# M460_v1 register map
File version: 1.0
Registers are 32-bit, read-write, reset 0x0 unless marked. A register's access mark holds for its fields unless they carry their own. Offsets are from the block's base; [hi:lo] are bit positions; lines under a group give offsets from that group.

## EMAC0 (part 1 of 2) — EMAC Register Map
Base 0x40012000
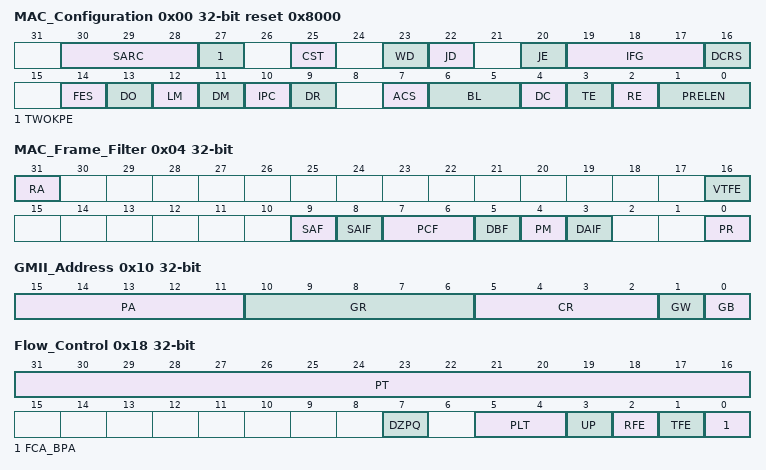
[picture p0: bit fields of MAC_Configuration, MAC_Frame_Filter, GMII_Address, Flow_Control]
0x00 MAC_Configuration reset 0x8000 — Register 0 (MAC Configuration Register)
  [30:28] SARC — Source Address Insertion or Replacement Control. This field controls the source address insertion or replacement for all transmitted frames. Bit 30 specifies which MAC Address register (0 or 1) is used for source address insertion or replacement based on the values of Bits [29:28]: If Bit 30 is set to 0, the MAC replaces the content of the MAC Address 0 registers (registers 16 and 17) in the SA field of all transmitted frames. If Bit 30 is set to 1, the MAC replaces the content of the MAC Address 1 registers (registers 18 and 19) in the SA field of all transmitted frames. Note: Changes to this field take effect only on the start of a frame. If you write this register field when a frame is being transmitted, only the subsequent frame can use the updated value, that is, the current frame does not use the updated value.
  [27] TWOKPE — IEEE 802.3as Support for 2K Packets. When set, the MAC considers all frames, with up to 2,000 bytes length, as normal packets. When Bit 20 (JE) is not set, the MAC considers all received frames of size more than 2 Kbytes as Giant frames. When this bit is reset and Bit 20 (JE) is not set, the MAC considers all received frames of size more than 1,518 bytes (1,522 bytes for tagged) as Giant frames. When Bit 20 is set, setting this bit has no effect on Giant Frame status.
  [25] CST — CRC Stripping for Type Frames. When this bit is set, the last 4 bytes (FCS) of all frames of Ether type (Length/Type field greater than or equal to 1,536) are stripped and dropped before forwarding the frame to the application. This function is not valid when the IP Checksum Engine (Type 1) is enabled in the MAC receiver. This function is valid when Type 2 Checksum Offload Engine is enabled.
  [23] WD — Watchdog Disable. When this bit is set, the MAC disables the watchdog timer on the receiver. The MAC can receive frames of up to 16,384 bytes. When this bit is reset, the MAC does not allow a receive frame which more than 2,048 bytes (10,240 if JE is set high) or the value programmed in Register 55 (Watchdog Timeout Register). The MAC cuts off any bytes received after the watchdog limit number of bytes.
  [22] JD — Jabber Disable. When this bit is set, the MAC disables the jabber timer on the transmitter. The MAC can transfer frames of up to 16,384 bytes. When this bit is reset, the MAC cuts off the transmitter if the application sends out more than 2,048 bytes of data (10,240 if JE is set high) during transmission.
  [20] JE — Jumbo Frame Enable. When this bit is set, the MAC allows Jumbo frames of 9,018 bytes (9,022 bytes for VLAN tagged frames) without reporting a giant frame error in the receive frame status.
  [19:17] IFG — Inter-Frame Gap. These bits control the minimum IFG between frames during transmission.
    0=96 bit times; 1=88 bit times; 2=80 bit times; 7=40 bit times
  [16] DCRS — Disable Carrier Sense During Transmission. When set high, this bit makes the MAC transmitter ignore the (G)MII CRS signal during frame transmission in the half-duplex mode. This request results in no errors generated because of Loss of Carrier or No Carrier during such transmission. When this bit is low, the MAC transmitter generates such errors because of Carrier Sense and can even abort the transmissions.
  [14] FES — Speed. This bit selects the speed in the RMII interface
    0=10 Mbps; 1=100 Mbps
  [13] DO — Disable Receive Own. When this bit is set, the MAC disables the reception of frames when the phy_txen_o is asserted in the half-duplex mode. When this bit is reset, the MAC receives all packets that are given by the PHY while transmitting. This bit is not applicable if the MAC is operating in the full-duplex mode.
  [12] LM — Loopback Mode. When this bit is set, the MAC operates in the loopback mode at MII. The (G)MII Receive clock input is required for the loopback to work properly, because the Transmit clock is not looped-back internally.
  [11] DM — Duplex Mode. When this bit is set, the MAC operates in the full-duplex mode where it can transmit and receive simultaneously.
  [10] IPC — Checksum Offload. When this bit is set, the MAC calculates the 16-bit one's complement of the one's complement sum of all received Ethernet frame payloads. It also checks whether the IPv4 Header checksum (assumed to be bytes 2526 or 2930 (VLAN-tagged) of the received Ethernet frame) is correct for the received frame and gives the status in the receive status word. The MAC also appends the 16-bit checksum calculated for the IP header datagram payload (bytes after the IPv4 header) and appends it to the Ethernet frame transferred to the application (when Type 2 COE is deselected). When this bit is reset, this function is disabled. When Type 2 COE is selected, this bit, when set, enables the IPv4 header checksum checking and IPv4 or IPv6 TCP, UDP, or ICMP payload checksum checking. When this bit is reset, the COE function in the receiver is disabled and the corresponding PCE and IP HCE status bits are always cleared.
  [9] DR — Disable Retry. When this bit is set, the MAC attempts only one transmission. When a collision occurs on the MII interface, the MAC ignores the current frame transmission and reports a Frame Abort with excessive collision error in the transmit frame status. When this bit is reset, the MAC attempts retries based on the settings of the BL field (Bits [6:5]). This bit is applicable only in the half-duplex mode.
  [7] ACS — Automatic Pad or CRC Stripping. When this bit is set, the MAC strips the Pad or FCS field on the incoming frames only if the value of the length field is less than 1,536 bytes. All received frames with length field greater than or equal to 1,536 bytes are passed to the application without stripping the Pad or FCS field. When this bit is reset, the MAC passes all incoming frames, without modifying them, to the Host.
  [6:5] BL — Back-Off Limit. The Back-Off limit determines the random integer number (r) of slot time delays (512 bit times for 10/100 Mbps) for which the MAC waits before rescheduling a transmission attempt during retries after a collision. This bit is applicable only in the half-duplex mode.
    0=k is the min of (n, 10); 1=k is the min of (n, 8); 2=k is the min of (n, 4); 3=k is the min of (n, 1)
  [4] DC — Deferral Check. When this bit is set, the deferral check function is enabled in the MAC. The MAC issues a Frame Abort status, along with the excessive deferral error bit set in the transmit frame status, when the transmit state machine is deferred for more than 24,288 bit times in the 10 or 100 Mbps mode. If the MAC is configured for 1000 Mbps operation or if the Jumbo frame mode is enabled in the 10 or 100 Mbps mode, the threshold for deferral is 155,680 bits times. Deferral begins when the transmitter is ready to transmit, but it is prevented because of an active carrier sense signal (CRS) on MII. The defer time is not cumulative. For example, if the transmitter defers for 10,000 bit times because the CRS signal is active and then the CRS signal becomes inactive, the transmitter transmits and collision happens. Because of collision, the transmitter needs to back off and then defer again after back off completion. In such a scenario, the deferral timer is reset to 0 and it is restarted. When this bit is reset, the deferral check function is disabled and the MAC defers until the CRS signal goes inactive. This bit is applicable only in the half-duplex mode.
  [3] TE — Transmitter Enable. When this bit is set, the transmit state machine of the MAC is enabled for transmission on the MII. When this bit is reset, the MAC transmit state machine is disabled after the completion of the transmission of the current frame, and does not transmit any further frames.
  [2] RE — Receiver Enable. When this bit is set, the receiver state machine of the MAC is enabled for receiving frames from the MII. When this bit is reset, the MAC receive state machine is disabled after the completion of the reception of the current frame, and does not receive any further frames from the MII.
  [1:0] PRELEN — Preamble Length for Transmit Frames. These bits control the number of preamble bytes that are added to the beginning of every Transmit frame. The preamble reduction occurs only when the MAC is operating in the full-duplex mode.
0x04 MAC_Frame_Filter — Register 1 (MAC Frame Filter)
  [31] RA — Receive All. When this bit is set, the MAC Receiver module passes all received frames, irrespective of whether they pass the address filter or not, to the Application. The result of the SA or DA filtering is updated (pass or fail) in the corresponding bits in the Receive Status Word. When this bit is reset, the Receiver module passes only those frames to the Application that pass the SA or DA address filter.
  [16] VTFE — VLAN Tag Filter Enable. When set, this bit enables the MAC to drop VLAN tagged frames that do not match the VLAN Tag comparison. When reset, the MAC forwards all frames irrespective of the match status of the VLAN Tag.
  [9] SAF — Source Address Filter Enable. When this bit is set, the MAC compares the SA field of the received frames with the values programmed in the enabled SA registers. If the comparison fails, the MAC drops the frame. When this bit is reset, the MAC forwards the received frame to the application with updated SAF bit of the Rx Status depending on the SA address comparison. Note: According to the IEEE specification, Bit 47 of the SA is reserved and set to 0. However, in EMAC, the MAC compares all 48 bits. The software driver should take this into consideration while programming the MAC address registers for SA.
  [8] SAIF — SA Inverse Filtering. When this bit is set, the Address Check block operates in inverse filtering mode for the SA address comparison. The frames whose SA matches the SA registers are marked as failing the SA Address filter. When this bit is reset, frames whose SA does not match the SA registers are marked as failing the SA Address filter.
  [7:6] PCF — Pass Control Frames. These bits control the forwarding of all control frames (including unicast and multicast PAUSE frames). The following conditions should be true for the PAUSE control frames processing: Condition 1: The MAC is in the full-duplex mode and flow control is enabled by setting Bit 2 (RFE) of Register 6 (Flow Control Register) to 1. Condition 2: The destination address (DA) of the received frame matches the special multicast address or the MAC Address 0 when Bit 3 (UP) of the Register 6 (Flow Control Register) is set. Condition 3: The Type field of the received frame is 0x8808 and the OPCODE field is 0x0001. Note: This field should be set to 01 only when the Condition 1 is true, that is, the MAC is programmed to operate in the full-duplex mode and the RFE bit is enabled. Otherwise, the PAUSE frame filtering may be inconsistent. When Condition 1 is false, the PAUSE frames are considered as generic control frames. Therefore, to pass all control frames (including PAUSE control frames) when the full-duplex mode and flow control is not enabled, you should set the PCF field to 10 or 11 (as required by the application).
    0=MAC filters all control frames from reaching the application; 1=MAC forwards all control frames except PAUSE control frames to application even if they fail the Address filter; 2=MAC forwards all control frames to application even if they fail the Address Filter; 3=MAC forwards control frames that pass the Address Filter
  [5] DBF — Disable Broadcast Frames. When this bit is set, the AFM module filters all incoming broadcast frames. In addition, it overrides all other filter settings. When this bit is reset, the AFM module passes all received broadcast frames.
  [4] PM — Pass All Multicast. When set, this bit indicates that all received frames with a multicast destination address (first bit in the destination address field is '1') are passed. When reset, filtering of multicast frame depends on HMC bit.
  [3] DAIF — DA Inverse Filtering. When this bit is set, the Address Check block operates in inverse filtering mode for the DA address comparison for both unicast and multicast frames. When reset, normal filtering of frames is performed.
  [0] PR — Promiscuous Mode. When this bit is set, the Address Filter module passes all incoming frames regardless of its destination or source address. The SA or DA Filter Fails status bits of the Receive Status Word are always cleared when PR is set.
0x10 GMII_Address — Register 4 (GMII Address Register)
  [15:11] PA — Physical Layer Address. This field indicates which of the 32 possible PHY devices are being accessed.
  [10:6] GR — GMII Register. These bits select the desired GMII register in the selected PHY device.
  [5:2] CR — CSR Clock Range
    0=The frequency of the CSR clock is 60-100 MHz and the MDC clock is CSR clock/42; 1=The frequency of the CSR clock is 100-150 MHz and the MDC clock is CSR clock/62; 2=The frequency of the CSR clock is 20-35 MHz and the MDC clock is CSR clock/16; 3=The frequency of the CSR clock is 35-60 MHz and the MDC clock is CSR clock/26; 4=The frequency of the CSR clock is 150-250 MHz and the MDC clock is CSR clock/102. The frequency of the CSR clock is 250-300 MHz and the MDC clock is CSR clock/124; 8=CSR clock/4; 9=CSR clock/6; 10=CSR clock/8; 11=CSR clock/10; 12=CSR clock/12; 13=CSR clock/14; 14=CSR clock/16; 15=CSR clock/18
  [1] GW — GMII Write. When set, this bit indicates to the PHY that this is a Write operation using the GMII Data register. If this bit is not set, it indicates that this is a Read operation, that is, placing the data in the GMII Data register.
  [0] GB — GMII Busy. This bit should read logic 0 before writing to Register 4 and Register 5. During a PHY register access, the software sets this bit to 1'b1 to indicate that a Read or Write access is in progress. Register 5 is invalid until this bit is cleared by the MAC. Therefore, Register 5 (GMII Data) should be kept valid until the MAC clears this bit during a PHY Write operation. Similarly for a read operation, the contents of Register 5 are not valid until this bit is cleared. The subsequent read or write operation should happen only after the previous operation is complete. Because there is no acknowledgment from the PHY to MAC after a read or write operation is completed, there is no change in the functionality of this bit even when the PHY is not present.
0x14 GMII_Data — Register 5 (GMII Data Register)
  [15:0] GD — GMII Data. This field contains the 16-bit data value read from the PHY after a Management Read operation or the 16-bit data value to be written to the PHY before a Management Write operation.
0x18 Flow_Control — Register 6 (Flow Control Register)
  [31:16] PT — Pause Time. This field holds the value to be used in the Pause Time field in the transmit control frame. Consecutive writes to this register should be performed only after at least four clock cycles in the destination clock domain.
  [7] DZPQ — Disable Zero-Quanta Pause. When this bit is set, it disables the automatic generation of the Zero-Quanta Pause Control frames on the de-assertion of the flow-control signal from the FIFO layer. When this bit is reset, normal operation with automatic Zero-Quanta Pause Control frame generation is enabled.
  [5:4] PLT — Pause Low Threshold. This field configures the threshold of the PAUSE timer at which the input flow control signal is checked for automatic retransmission of PAUSE Frame. The slot time is defined as the time taken to transmit 512 bits (64 bytes) on the MII interface.
    0=The threshold is Pause time minus 4 slot times (PT - 4 slot times); 1=The threshold is Pause time minus 28 slot times (PT - 28 slot times); 2=The threshold is Pause time minus 144 slot times (PT - 144 slot times); 3=The threshold is Pause time minus 256 slot times (PT - 256 slot times)
  [3] UP — Unicast Pause Frame Detect. A pause frame is processed when it has the unique multicast address specified in the IEEE Std 802.3. When this bit is set, the MAC can also detect Pause frames with unicast address of the station. This unicast address should be as specified in the MAC Address0 High Register and MAC Address0 Low Register. When this bit is reset, the MAC only detects Pause frames with unique multicast address. Note: The MAC does not process a Pause frame if the multicast address of received frame is different from the unique multicast address.
  [2] RFE — Receive Flow Control Enable. When this bit is set, the MAC decodes the received Pause frame and disables its transmitter for a specified (Pause) time. When this bit is reset, the decode function of the Pause frame is disabled.
  [1] TFE — Transmit Flow Control Enable. In the full-duplex mode, when this bit is set, the MAC enables the flow control operation to transmit Pause frames. When this bit is reset, the flow control operation in the MAC is disabled, and the MAC does not transmit any Pause frames. In half-duplex mode, when this bit is set, the MAC enables the back-pressure operation. When this bit is reset, the back-pressure feature is disabled.
  [0] FCA_BPA — Flow Control Busy or Backpressure Activate. This bit initiates a Pause Control frame in the full-duplex mode and activates the backpressure function in the half-duplex mode if the TFE bit is set. In the full-duplex mode, this bit should be read as 1'b0 before writing to the Flow Control register. To initiate a Pause control frame, the Application must set this bit to 1'b1. During a transfer of the Control Frame, this bit continues to be set to signify that a frame transmission is in progress. After the completion of Pause control frame transmission, the MAC resets this bit to 1'b0. The Flow Control register should not be written to until this bit is cleared. In the half-duplex mode, when this bit is set (and TFE is set), then backpressure is asserted by the MAC. During backpressure, when the MAC receives a new frame, the transmitter starts sending a JAM pattern resulting in a collision. This control register bit is logically ORed with the mti_flowctrl_i input signal for the backpressure function. When the MAC is configured for the full-duplex mode, the BPA is automatically disabled.
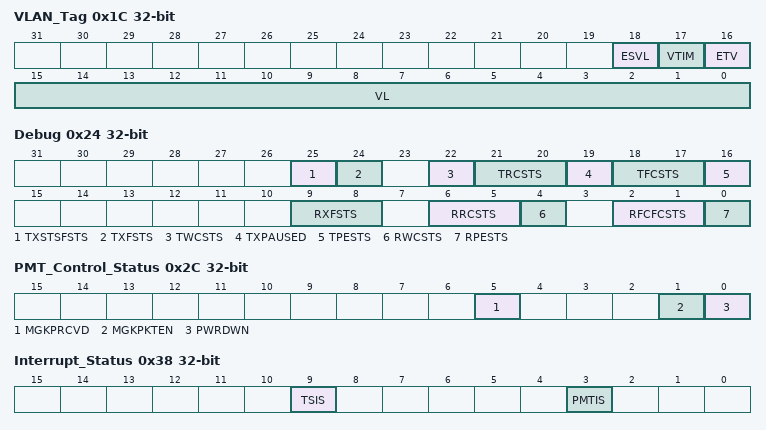
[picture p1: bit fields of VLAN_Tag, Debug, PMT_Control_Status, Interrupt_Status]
0x1C VLAN_Tag — Register 7 (VLAN Tag Register)
  [18] ESVL — Enable S-VLAN
  [17] VTIM — VLAN Tag Inverse Match Enable. When set, this bit enables the VLAN Tag inverse matching. The frames that do not have matching VLAN Tag are marked as matched. When reset, this bit enables the VLAN Tag perfect matching. The frames with matched VLAN Tag are marked as matched.
  [16] ETV — Enable 12-Bit VLAN Tag Comparison. When this bit is set, a 12-bit VLAN identifier is used for comparing and filtering instead of the complete 16-bit VLAN tag. Bits [11:0] of VLAN tag are compared with the corresponding field in the received VLAN-tagged frame. Similarly, when enabled, only 12 bits of the VLAN tag in the received frame are used for hash-based VLAN filtering. When this bit is reset, all 16 bits of the 15th and 16th bytes of the received VLAN frame are used for comparison and VLAN hash filtering.
  [15:0] VL — VLAN Tag Identifier for Receive Frames. This field contains the 802.1Q VLAN tag to identify the VLAN frames and is compared to the 15th and 16th bytes of the frames being received for VLAN frames. The following list describes the bits of this field: Bits [15:13]: User Priority. Bit 12: Canonical Format Indicator (CFI) or Drop Eligible Indicator (DEI). Bits [11:0]: VLAN tag's VLAN Identifier (VID) field. When the ETV bit is set, only the VID (Bits [11:0]) is used for comparison. If VL (VL[11:0] if ETV is set) is all zeros, the MAC does not check the fifteenth and 16th bytes for VLAN tag comparison, and declares all frames with a Type field value of 0x8100 or 0x88a8 as VLAN frames.
0x20 Version ro reset 0x1037 — Register 8 (Version Register)
0x24 Debug ro — Register 9 (Debug Register)
  [25] TXSTSFSTS — MTL TxStatus FIFO Full Status. When high, this bit indicates that the MTL TxStatus FIFO is full. Therefore, the MTL cannot accept any more frames for transmission.
  [24] TXFSTS — MTL Tx FIFO Not Empty Status. When high, this bit indicates that the MTL Tx FIFO is not empty and some data is left for transmission.
  [22] TWCSTS — MTL Tx FIFO Write Controller Active Status. When high, this bit indicates that the MTL Tx FIFO Write Controller is active and transferring data to the Tx FIFO.
  [21:20] TRCSTS — MTL Tx FIFO Read Controller Status. This field indicates the state of the Tx FIFO Read Controller:
    0=IDLE state; 1=READ state (transferring data to MAC transmitter); 2=Waiting for TxStatus from MAC transmitter; 3=Writing the received TxStatus or flushing the Tx FIFO
  [19] TXPAUSED — MAC transmitter in PAUSE. When high, this bit indicates that the MAC transmitter is in the PAUSE condition (in the full-duplex only mode) and hence does not schedule any frame for transmission.
  [18:17] TFCSTS — MAC Transmit Frame Controller Status. This field indicates the state of the MAC Transmit Frame Controller module:
    0=IDLE state; 1=Waiting for Status of previous frame or IFG or backoff period to be over; 2=Generating and transmitting a PAUSE control frame (in the full-duplex mode); 3=Transferring input frame for transmission
  [16] TPESTS — MAC MII Transmit Protocol Engine Status. When high, this bit indicates that the MAC MII transmit protocol engine is actively transmitting data and is not in the IDLE state.
  [9:8] RXFSTS — MTL Rx FIFO Fill-level Status. This field gives the status of the fill-level of the Rx FIFO:
    0=Rx FIFO Empty; 1=Rx FIFO fill level is below the flow-control deactivate threshold; 2=Rx FIFO fill level is above the flow-control activate threshold; 3=Rx FIFO Full
  [6:5] RRCSTS — MTL Rx FIFO Read Controller State. This field gives the state of the Rx FIFO read Controller:
    0=IDLE state; 1=Reading frame data; 2=Reading frame status (or timestamp); 3=Flushing the frame data and status
  [4] RWCSTS — MTL Rx FIFO Write Controller Active Status. When high, this bit indicates that the MTL Rx FIFO Write Controller is active and is transferring a received frame to the FIFO.
  [2:1] RFCFCSTS — MAC Receive Frame Controller FIFO Status. When high, this field indicates the active state of the small FIFO Read and Write controllers of the MAC Receive Frame Controller Module.
  [0] RPESTS — MAC MII Receive Protocol Engine Status. When high, this bit indicates that the MAC MII receive protocol engine is actively receiving data and not in IDLE state.
0x2C PMT_Control_Status — Register 11 (PMT Control and Status Register)
  [5] MGKPRCVD ro — Magic Packet Received (read only). When set, this bit indicates that the power management event is generated because of the reception of a magic packet. This bit is cleared by a Read into this register.
  [1] MGKPKTEN — Magic Packet Enable. When set, enables generation of a power management event because of magic packet reception.
  [0] PWRDWN — Power Down. When set, the MAC receiver drops all received frames until it receives the expected magic packet or wake-up frame. This bit is then self-cleared and the power-down mode is disabled. The Software can also clear this bit before the expected magic packet or wake-up frame is received. The frames, received by the MAC after this bit is cleared, are forwarded to the application. This bit must only be set when the Magic Packet Enable, Global Unicast, or Wake-Up Frame Enable bit is set high. Note: You can gate-off the CSR clock during the power-down mode. However, when the CSR clock is gated-off, you cannot perform any read or write operations on this register. Therefore, the Software cannot clear this bit.
0x38 Interrupt_Status ro — Register 14 (Interrupt Register)
  [9] TSIS — Timestamp Interrupt Status. When the Advanced Timestamp feature is enabled, this bit is set when any of the following conditions is true: The system time value equals or exceeds the value specified in the Target Time High and Low registers. There is an overflow in the seconds register. The Auxiliary snapshot trigger is asserted. This bit is cleared on reading Bit 0 of the Register 458 (Timestamp Status Register). If default Timestamping is enabled, when set, this bit indicates that the system time value is equal to or exceeds the value specified in the Target Time registers. In this mode, this bit is cleared after the completion of the read of this bit. In all other modes, this bit is reserved.
  [3] PMTIS — PMT Interrupt Status. This bit is set when a Magic packet or Wake-on-LAN frame is received in the power-down mode (see Bits 5 in the PMT Control and Status Register). This bit is cleared when Bit 5 is cleared because of a read operation to the PMT Control and Status register.
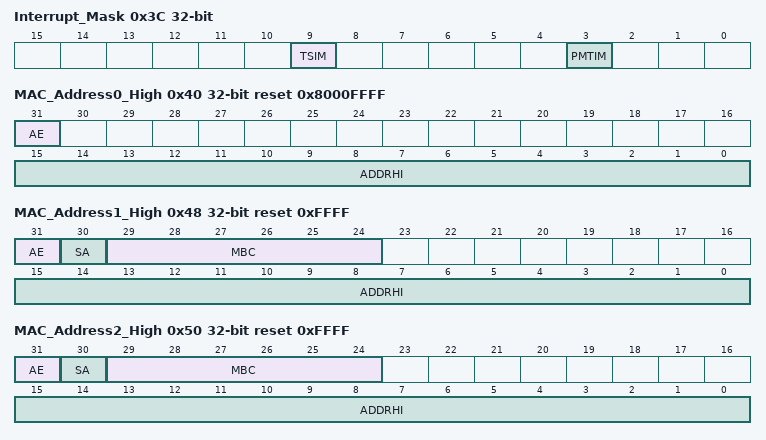
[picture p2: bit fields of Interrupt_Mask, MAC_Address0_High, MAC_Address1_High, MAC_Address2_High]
0x3C Interrupt_Mask — Register 15 (Interrupt Mask Register)
  [9] TSIM — Timestamp Interrupt Mask. When set, this bit disables the assertion of the interrupt signal because of the setting of Timestamp Interrupt Status bit in Register 14 (Interrupt Status Register). This bit is valid only when IEEE1588 timestamping is enabled. In all other modes, this bit is reserved.
  [3] PMTIM — PMT Interrupt Mask. When set, this bit disables the assertion of the interrupt signal because of the setting of PMT Interrupt Status bit in Register 14 (Interrupt Status Register).
0x40 MAC_Address0_High reset 0x8000FFFF — Register 16 (MAC Address0 High Register)
  [31] AE ro — Address Enable (read only). This bit is always set to 1.
  [15:0] ADDRHI — MAC Address0 [47:32]. This field contains the upper 16 bits (47:32) of the first 6-byte MAC address. The MAC uses this field for filtering the received frames and inserting the MAC address in the Transmit Flow Control (PAUSE) Frames.
0x44 MAC_Address0_Low reset 0xFFFFFFFF — Register 17 (MAC Address0 Low Register)
  [31:0] ADDRLO — MAC Address0 [31:0]. This field contains the lower 32 bits of the first 6-byte MAC address. This is used by the MAC for filtering the received frames and inserting the MAC address in the Transmit Flow Control (PAUSE) Frames.
0x48 MAC_Address1_High reset 0xFFFF — Register 18 (MAC Address1 High Register)
  [31] AE — Address Enable. When this bit is set, the address filter module uses the second MAC address for perfect filtering. When this bit is reset, the address filter module ignores the address for filtering.
  [30] SA — Source Address. When this bit is set, the MAC Address1[47:0] is used to compare with the SA fields of the received frame. When this bit is reset, the MAC Address1[47:0] is used to compare with the DA fields of the received frame.
  [29:24] MBC — Mask Byte Control. These bits are mask control bits for comparison of each of the MAC Address bytes. When set high, the MAC does not compare the corresponding byte of received DA or SA with the contents of MAC Address1 registers. Each bit controls the masking of the bytes as follows: Bit 29: Register 18[15:8]. Bit 28: Register 18[7:0]. Bit 27: Register 19[31:24] ... Bit 24: Register 19[7:0]. You can filter a group of addresses (known as group address filtering) by masking one or more bytes of the address.
  [15:0] ADDRHI — MAC Address1 [47:32]. This field contains the upper 16 bits (47:32) of the second 6-byte MAC address.
0x4C MAC_Address1_Low reset 0xFFFFFFFF — Register 19 (MAC Address1 Low Register)
  [31:0] ADDRLO — MAC Address1 [31:0]. This field contains the lower 32 bits of the second 6-byte MAC address. The content of this field is undefined until loaded by the Application after the initialization process.
0x50 MAC_Address2_High reset 0xFFFF — Register 20 (MAC Address2 High Register)
  [31] AE — Address Enable. When this bit is set, the address filter module uses the third MAC address for perfect filtering. When this bit is reset, the address filter module ignores the address for filtering.
  [30] SA — Source Address. When this bit is set, the MAC Address2[47:0] is used to compare with the SA fields of the received frame. When this bit is reset, the MAC Address2[47:0] is used to compare with the DA fields of the received frame.
  [29:24] MBC — Mask Byte Control. These bits are mask control bits for comparison of each of the MAC Address bytes. When set high, the MAC does not compare the corresponding byte of received DA or SA with the contents of MAC Address2 registers. Each bit controls the masking of the bytes as follows: Bit 29: Register 18[15:8]. Bit 28: Register 18[7:0]. Bit 27: Register 19[31:24] ... Bit 24: Register 19[7:0]
  [15:0] ADDRHI — MAC Address2 [47:32]. This field contains the upper 16 bits (47:32) of the third 6-byte MAC address.
0x54 MAC_Address2_Low reset 0xFFFFFFFF — Register 21 (MAC Address2 Low Register)
  [31:0] ADDRLO — MAC Address2 [31:0]. This field contains the lower 32 bits of the third 6-byte MAC address. The content of this field is undefined until loaded by the Application after the initialization process.
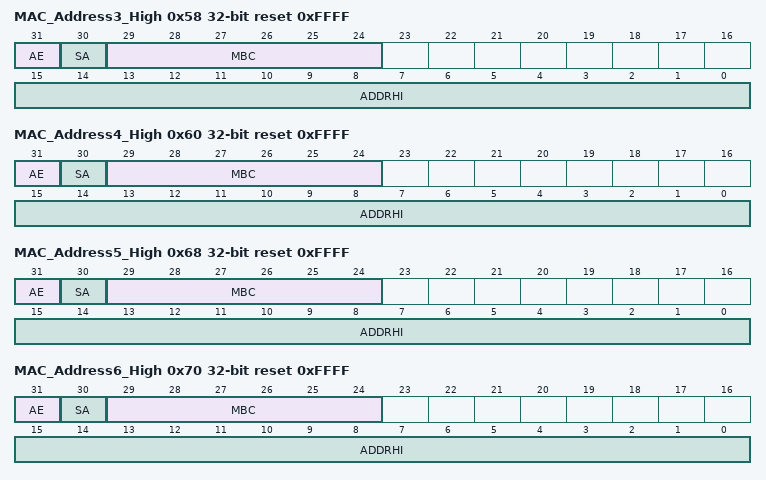
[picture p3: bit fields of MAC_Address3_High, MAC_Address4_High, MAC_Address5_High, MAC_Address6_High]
0x58 MAC_Address3_High reset 0xFFFF — Register 22 (MAC Address3 High Register)
  [31] AE — Address Enable. When this bit is set, the address filter module uses the fourth MAC address for perfect filtering. When this bit is reset, the address filter module ignores the address for filtering.
  [30] SA — Source Address. When this bit is set, the MAC Address3[47:0] is used to compare with the SA fields of the received frame. When this bit is reset, the MAC Address3[47:0] is used to compare with the DA fields of the received frame.
  [29:24] MBC — Mask Byte Control. These bits are mask control bits for comparison of each of the MAC Address bytes. When set high, the MAC does not compare the corresponding byte of received DA or SA with the contents of MAC Address3 registers. Each bit controls the masking of the bytes as follows: Bit 29: Register 18[15:8]. Bit 28: Register 18[7:0]. Bit 27: Register 19[31:24] ... Bit 24: Register 19[7:0]
  [15:0] ADDRHI — MAC Address3 [47:32]. This field contains the upper 16 bits (47:32) of the fourth 6-byte MAC address.
0x5C MAC_Address3_Low reset 0xFFFFFFFF — Register 23 (MAC Address3 Low Register)
  [31:0] ADDRLO — MAC Address3 [31:0]. This field contains the lower 32 bits of the fourth 6-byte MAC address. The content of this field is undefined until loaded by the Application after the initialization process.
0x60 MAC_Address4_High reset 0xFFFF — Register 24 (MAC Address4 High Register)
  [31] AE — Address Enable. When this bit is set, the address filter module uses the fifth MAC address for perfect filtering. When this bit is reset, the address filter module ignores the address for filtering.
  [30] SA — Source Address. When this bit is set, the MAC Address4[47:0] is used to compare with the SA fields of the received frame. When this bit is reset, the MAC Address4[47:0] is used to compare with the DA fields of the received frame.
  [29:24] MBC — Mask Byte Control. These bits are mask control bits for comparison of each of the MAC Address bytes. When set high, the MAC does not compare the corresponding byte of received DA or SA with the contents of MAC Address4 registers. Each bit controls the masking of the bytes as follows: Bit 29: Register 18[15:8]. Bit 28: Register 18[7:0]. Bit 27: Register 19[31:24] ... Bit 24: Register 19[7:0]
  [15:0] ADDRHI — MAC Address4 [47:32]. This field contains the upper 16 bits (47:32) of the fifth 6-byte MAC address.
0x64 MAC_Address4_Low reset 0xFFFFFFFF — Register 25 (MAC Address4 Low Register)
  [31:0] ADDRLO — MAC Address4 [31:0]. This field contains the lower 32 bits of the fifth 6-byte MAC address. The content of this field is undefined until loaded by the Application after the initialization process.
0x68 MAC_Address5_High reset 0xFFFF — Register 26 (MAC Address5 High Register)
  [31] AE — Address Enable. When this bit is set, the address filter module uses the sixth MAC address for perfect filtering. When this bit is reset, the address filter module ignores the address for filtering.
  [30] SA — Source Address. When this bit is set, the MAC Address5[47:0] is used to compare with the SA fields of the received frame. When this bit is reset, the MAC Address5[47:0] is used to compare with the DA fields of the received frame.
  [29:24] MBC — Mask Byte Control. These bits are mask control bits for comparison of each of the MAC Address bytes. When set high, the MAC does not compare the corresponding byte of received DA or SA with the contents of MAC Address5 registers. Each bit controls the masking of the bytes as follows: Bit 29: Register 18[15:8]. Bit 28: Register 18[7:0]. Bit 27: Register 19[31:24] ... Bit 24: Register 19[7:0]
  [15:0] ADDRHI — MAC Address5 [47:32]. This field contains the upper 16 bits (47:32) of the sixth 6-byte MAC address.
0x6C MAC_Address5_Low reset 0xFFFFFFFF — Register 27 (MAC Address5 Low Register)
  [31:0] ADDRLO — MAC Address5 [31:0]. This field contains the lower 32 bits of the sixth 6-byte MAC address. The content of this field is undefined until loaded by the Application after the initialization process.
0x70 MAC_Address6_High reset 0xFFFF — Register 28 (MAC Address6 High Register)
  [31] AE — Address Enable. When this bit is set, the address filter module uses the seventh MAC address for perfect filtering. When this bit is reset, the address filter module ignores the address for filtering.
  [30] SA — Source Address. When this bit is set, the MAC Address6[47:0] is used to compare with the SA fields of the received frame. When this bit is reset, the MAC Address6[47:0] is used to compare with the DA fields of the received frame.
  [29:24] MBC — Mask Byte Control. These bits are mask control bits for comparison of each of the MAC Address bytes. When set high, the MAC does not compare the corresponding byte of received DA or SA with the contents of MAC Address6 registers. Each bit controls the masking of the bytes as follows: Bit 29: Register 18[15:8]. Bit 28: Register 18[7:0]. Bit 27: Register 19[31:24] ... Bit 24: Register 19[7:0]
  [15:0] ADDRHI — MAC Address6 [47:32]. This field contains the upper 16 bits (47:32) of the seventh 6-byte MAC address.
0x74 MAC_Address6_Low reset 0xFFFFFFFF — Register 29 (MAC Address6 Low Register)
  [31:0] ADDRLO — MAC Address6 [31:0]. This field contains the lower 32 bits of the seventh 6-byte MAC address. The content of this field is undefined until loaded by the Application after the initialization process.
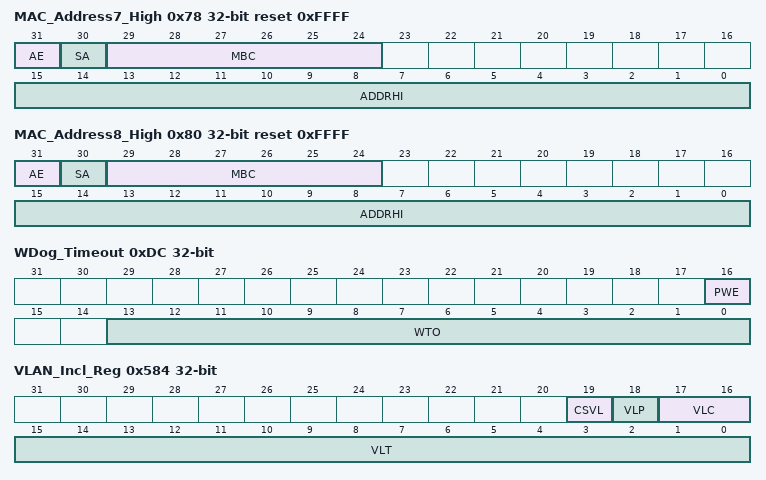
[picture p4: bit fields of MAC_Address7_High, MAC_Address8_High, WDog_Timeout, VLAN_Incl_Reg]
0x78 MAC_Address7_High reset 0xFFFF — Register 30 (MAC Address7 High Register)
  [31] AE — Address Enable. When this bit is set, the address filter module uses the eighth MAC address for perfect filtering. When this bit is reset, the address filter module ignores the address for filtering.
  [30] SA — Source Address. When this bit is set, the MAC Address7[47:0] is used to compare with the SA fields of the received frame. When this bit is reset, the MAC Address7[47:0] is used to compare with the DA fields of the received frame.
  [29:24] MBC — Mask Byte Control. These bits are mask control bits for comparison of each of the MAC Address bytes. When set high, the MAC does not compare the corresponding byte of received DA or SA with the contents of MAC Address6 registers. Each bit controls the masking of the bytes as follows: Bit 29: Register 18[15:8]. Bit 28: Register 18[7:0]. Bit 27: Register 19[31:24] ... Bit 24: Register 19[7:0]
  [15:0] ADDRHI — MAC Address7 [47:32]. This field contains the upper 16 bits (47:32) of the eighth 6-byte MAC address.
0x7C MAC_Address7_Low reset 0xFFFFFFFF — Register 31 (MAC Address7 Low Register)
  [31:0] ADDRLO — MAC Address7 [31:0]. This field contains the lower 32 bits of the eighth 6-byte MAC address. The content of this field is undefined until loaded by the Application after the initialization process.
0x80 MAC_Address8_High reset 0xFFFF — Register 32 (MAC Address8 High Register)
  [31] AE — Address Enable. When this bit is set, the address filter module uses the nineth MAC address for perfect filtering. When this bit is reset, the address filter module ignores the address for filtering.
  [30] SA — Source Address. When this bit is set, the MAC Address8[47:0] is used to compare with the SA fields of the received frame. When this bit is reset, the MAC Address8[47:0] is used to compare with the DA fields of the received frame.
  [29:24] MBC — Mask Byte Control. These bits are mask control bits for comparison of each of the MAC Address bytes. When set high, the MAC does not compare the corresponding byte of received DA or SA with the contents of MAC Address8 registers. Each bit controls the masking of the bytes as follows: Bit 29: Register 18[15:8]. Bit 28: Register 18[7:0]. Bit 27: Register 19[31:24] ... Bit 24: Register 19[7:0]
  [15:0] ADDRHI — MAC Address8 [47:32]. This field contains the upper 16 bits (47:32) of the nineth 6-byte MAC address.
0x84 MAC_Address8_Low reset 0xFFFFFFFF — Register 33 (MAC Address8 Low Register)
  [31:0] ADDRLO — MAC Address8 [31:0]. This field contains the lower 32 bits of the nineth 6-byte MAC address. The content of this field is undefined until loaded by the Application after the initialization process.
0xDC WDog_Timeout — Register 55 (Watchdog Timeout Register)
  [16] PWE — Programmable Watchdog Enable. When this bit is set and Bit 23 (WD) of Register 0 (MAC Configuration Register) is reset, the WTO field (Bits[13:0]) is used as watchdog timeout for a received frame. When this bit is cleared, the watchdog timeout for a received frame is controlled by the setting of Bit 23 (WD) and Bit 20 (JE) in Register 0 (MAC Configuration Register).
  [13:0] WTO — Watchdog Timeout. When Bit 16 (PWE) is set and Bit 23 (WD) of Register 0 (MAC Configuration Register) is reset, this field is used as watchdog timeout for a received frame. If the length of a received frame exceeds the value of this field, such frame is terminated and declared as an error frame. Note: When Bit 16 (PWE) is set, the value in this field should be more than 1,522 (0x05F2). Otherwise, the IEEE Std 802.3-specified valid tagged frames are declared as error frames and are dropped.
0x584 VLAN_Incl_Reg — Register 353 (VLAN Tag Inclusion or Replacement Register)
  [19] CSVL — C-VLAN or S-VLAN. When this bit is set, S-VLAN type (0x88A8) is inserted or replaced in the 13th and 14th bytes of transmitted frames. When this bit is reset, C-VLAN type (0x8100) is inserted or replaced in the transmitted frames.
  [18] VLP — VLAN Priority Control. When this bit is set, the control Bits [17:16] are used for VLAN deletion, insertion, or replacement. When this bit is reset, the mti_vlan_ctrl_i control input is used, and Bits [17:16] are ignored.
  [17:16] VLC — VLAN Tag Control in Transmit Frames. The MAC replaces VLT in bytes 15 and 16 of all VLAN-type transmitted frames (Bytes 13 and 14 are 0x8100/0x88a8). Note: Changes to this field take effect only on the start of a frame. If you write this register field when a frame is being transmitted, only the subsequent frame can use the updated value, that is, the current frame does not use the updated value
  [15:0] VLT — VLAN Tag for Transmit Frames. This field contains the value of the VLAN tag to be inserted or replaced. The value must only be changed when the transmit lines are inactive or during the initialization phase. Bits [15:13] are the User Priority, Bit 12 is the CFI/DEI, and Bits [11:0] are the VLAN tag's VID field.
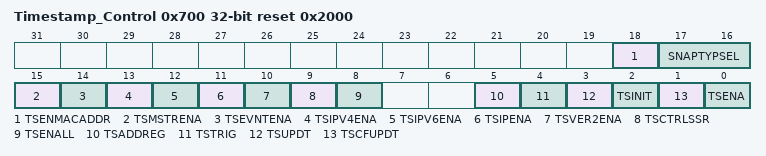
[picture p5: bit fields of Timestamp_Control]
0x700 Timestamp_Control reset 0x2000 — Register 448 (Timestamp Control Register)
  [18] TSENMACADDR — Enable MAC address for PTP Frame Filtering. When set, the DA MAC address (that matches any MAC Address register) is used to filter the PTP frames when PTP is directly sent over Ethernet.
  [17:16] SNAPTYPSEL — Select PTP packets for Taking Snapshots. These bits along with Bits 15 and 14 decide the set of PTP packet types for which snapshot needs to be taken.
  [15] TSMSTRENA — Enable Snapshot for Messages Relevant to Master. When set, the snapshot is taken only for the messages relevant to the master node. Otherwise, the snapshot is taken for the messages relevant to the slave node.
  [14] TSEVNTENA — Enable Timestamp Snapshot for Event Messages. When set, the timestamp snapshot is taken only for event messages (SYNC, Delay_Req, Pdelay_Req, or Pdelay_Resp). When reset, the snapshot is taken for all messages except Announce, Management, and Signaling.
  [13] TSIPV4ENA — Enable Processing of PTP Frames Sent over IPv4-UDP. When set, the MAC receiver processes the PTP packets encapsulated in UDP over IPv4 packets. When this bit is clear, the MAC ignores the PTP transported over UDP-IPv4 packets. This bit is set by default.
  [12] TSIPV6ENA — Enable Processing of PTP Frames Sent Over IPv6-UDP. When set, the MAC receiver processes PTP packets encapsulated in UDP over IPv6 packets. When this bit is clear, the MAC ignores the PTP transported over UDP-IPv6 packets.
  [11] TSIPENA — Enable Processing of PTP over Ethernet Frames. When set, the MAC receiver processes the PTP packets encapsulated directly in the Ethernet frames. When this bit is clear, the MAC ignores the PTP over Ethernet packets.
  [10] TSVER2ENA — Enable PTP packet Processing for Version 2 Format. When set, the PTP packets are processed using the 1588 version 2 format. Otherwise, the PTP packets are processed using the version 1 format.
  [9] TSCTRLSSR — Timestamp Digital or Binary Rollover Control. When set, the Timestamp Low register rolls over after 0x3B9A_C9FF value (that is, 1 nanosecond accuracy) and increments the timestamp (High) seconds. When reset, the rollover value of sub-second register is 0x7FFF_FFFF. The sub-second increment has to be programmed correctly depending on the PTP reference clock frequency and the value of this bit.
  [8] TSENALL — Enable Timestamp for All Frames. When set, the timestamp snapshot is enabled for all frames received by the MAC.
  [5] TSADDREG — Addend Reg Update. When set, the content of the Timestamp Addend register is updated in the PTP block for fine correction. This is cleared when the update is completed. This register bit should be zero before setting it.
  [4] TSTRIG — Timestamp Interrupt Trigger Enable. When set, the timestamp interrupt is generated when the System Time becomes greater than the value written in the Target Time register. This bit is reset after the generation of the Timestamp Trigger Interrupt.
  [3] TSUPDT — Timestamp Update. When set, the system time is updated (added or subtracted) with the value specified in Register 452 (System Time - Seconds Update Register) and Register 453 (System Time - Nanoseconds Update Register). This bit should be read zero before updating it. This bit is reset when the update is completed in hardware. The Timestamp Higher Word register is not updated.
  [2] TSINIT — Timestamp Initialize. When set, the system time is initialized (overwritten) with the value specified in the Register 452 (System Time - Seconds Update Register) and Register 453 (System Time - Nanoseconds Update Register). This bit should be read zero before updating it. This bit is reset when the initialization is complete. The Timestamp Higher Word register can only be initialized.
  [1] TSCFUPDT — Timestamp Fine or Coarse Update. When set, this bit indicates that the system times update should be done using the fine update method. When reset, it indicates the system timestamp update should be done using the Coarse method.
  [0] TSENA — Timestamp Enable. When set, the timestamp is added for the transmit and receive frames. When disabled, timestamp is not added for the transmit and receive frames and the Timestamp Generator is also suspended. You need to initialize the Timestamp (system time) after enabling this mode. On the receive side, the MAC processes the 1588 frames only if this bit is set.
